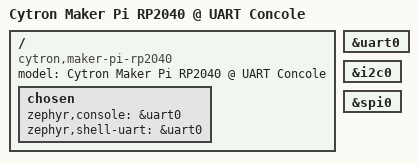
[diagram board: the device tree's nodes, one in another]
/*
 * Copyright (c) 2023-2025 TiaC Systems
 * SPDX-License-Identifier: Apache-2.0
 */

/dts-v1/;

/ {
	model = "Cytron Maker Pi RP2040 @ UART Concole";
	compatible = "cytron,maker-pi-rp2040", "cytron,maker-pi-rp2040-uartcons";

	chosen {
		zephyr,console = &uart0;
		zephyr,shell-uart = &uart0;
	};
};

#include "cytron_rp2040-makerpi.dtsi"
#include "cytron_rp2040-2mb.dtsi"

#include "maker_buzzer.dtsi"

#include "makerpi_button.dtsi"
#include "makerpi_led_mono.dtsi"
#include "makerpi_led_ws2812.dtsi"

#include "makerpi_servo.dtsi"

#include "makerpi_grove_connectors.dtsi"

grove_serial: &uart0 {};
grove_i2c: &i2c0 {};
grove_spi: &spi0 {};
